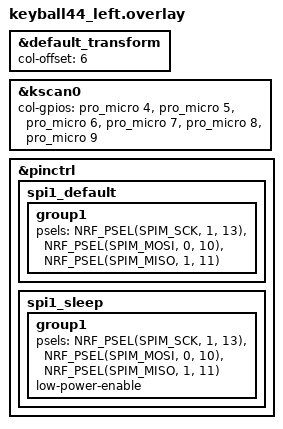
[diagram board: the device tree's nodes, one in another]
/*
 * Copyright (c) 2020 ZMK Contributors
 *
 * SPDX-License-Identifier: MIT
 */

#include "keyball44.dtsi"

&default_transform {
    col-offset = <6>;
};

&kscan0 {
    col-gpios
        = <&pro_micro 4 GPIO_ACTIVE_HIGH>
        , <&pro_micro 5 GPIO_ACTIVE_HIGH>
        , <&pro_micro 6 GPIO_ACTIVE_HIGH>
        , <&pro_micro 7 GPIO_ACTIVE_HIGH>
        , <&pro_micro 8 GPIO_ACTIVE_HIGH>
        , <&pro_micro 9 GPIO_ACTIVE_HIGH>
        ;
};

/* ---------------------------------------------------------
 * Trackball (RIGHT only)
 *  - i2c0(TWIM0) と spi0(SPIM0) が衝突するので spi1 に逃がす
 * --------------------------------------------------------- */

&pinctrl {
    spi1_default: spi1_default {
        group1 {
            psels = <NRF_PSEL(SPIM_SCK, 1, 13)>,
                    <NRF_PSEL(SPIM_MOSI, 0, 10)>,
                    <NRF_PSEL(SPIM_MISO, 1, 11)>;
        };
    };

    spi1_sleep: spi1_sleep {
        group1 {
            psels = <NRF_PSEL(SPIM_SCK, 1, 13)>,
                    <NRF_PSEL(SPIM_MOSI, 0, 10)>,
                    <NRF_PSEL(SPIM_MISO, 1, 11)>;
            low-power-enable;
        };
    };
};

